# STM32U335 register map
File version: 1.0
CPU: CM33 r0p1, little endian, MPU, FPU, 4 interrupt priority bits
Registers are 32-bit, read-write, reset 0x0 unless marked. A register's access mark holds for its fields unless they carry their own. Offsets are from the block's base; [hi:lo] are bit positions.

## GTZC1_TZSC — GTZC1_TZSC Address block
Base 0x40032400
Same registers: GTZC1_TZSC_S 0x50032400
0x00 GTZC1_TZSC_CR — Secure privileged access only.
  [0] LCK — lock the configuration of GTZC1_TZSC_SECCFGRx and GTZC1_TZSC_PRIVCFGRx registers until next reset This bit is cleared by default and once set, it can not be reset until system reset.
    0=configuration of all GTZC1_TZSC_SECCFGRx and GTZC1_TZSC_PRIVCFGRx registers not locked; 1=configuration of all GTZC1_TZSC_SECCFGRx and GTZC1_TZSC_PRIVCFGRx registers locked
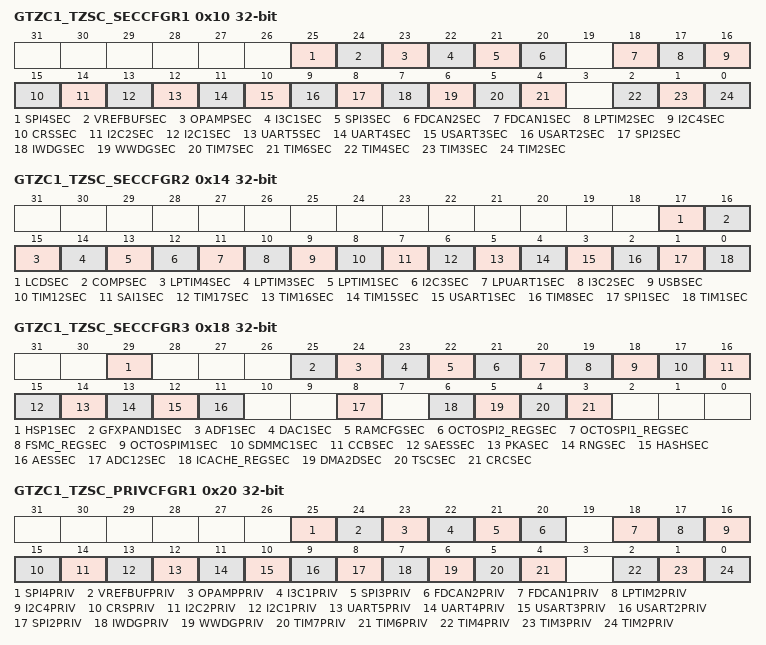
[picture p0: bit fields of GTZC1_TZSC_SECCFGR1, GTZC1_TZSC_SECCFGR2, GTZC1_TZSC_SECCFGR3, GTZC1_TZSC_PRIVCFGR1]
0x10 GTZC1_TZSC_SECCFGR1 — Write-secure access only. This register can be written only by secure privileged transaction when corresponding GTZC1_TZSC_PRIVCFGR register signal is set to 1. If a given PRIV bit is not set, the equivalent SEC bit can be written by secure unprivileged transaction. Read accesses are authorized for any type of transactions, secure or not, privileged or not.
  [all] fields
    0=non-secure; 1=secure
  [25] SPI4SEC — secure access mode for SPI4 Note: this bit is only available on STM32U3B5/3C5.
  [24] VREFBUFSEC — secure access mode for VREFBUF Note: this bit is not available on STM32U335/345.
  [23] OPAMPSEC — secure access mode for OPAMP
  [22] I3C1SEC — secure access mode for I3C1
  [21] SPI3SEC — secure access mode for SPI3 Note: this bit is not available on STM32U335/345.
  [20] FDCAN2SEC — secure access mode for FDCAN2 Caution: The FDCAN SRAM is secure only when all FDCAN instances are configures as secure Note: This bit is only available on STM32U3B5/3C5
  [18] FDCAN1SEC — secure access mode for FDCAN1 Caution: The FDCAN SRAM is secure only when all FDCAN instances are configures as secure Note: This bit is not available on STM32U356/366.
  [17] LPTIM2SEC — secure access mode for LPTIM2
  [16] I2C4SEC — secure access mode for I2C4 Note: This bit is only available on STM32U3B5/3C5
  [15] CRSSEC — secure access mode for CRS
  [14] I2C2SEC — secure access mode for I2C2 Note: This bit is only available on STM32U375/385, STM32U396/3A6, and STM32U3B5/3C5.
  [13] I2C1SEC — secure access mode for I2C1
  [12] UART5SEC — secure access mode for UART5 Note: This bit is not available on STM32U335/345.
  [11] UART4SEC — secure access mode for UART4
  [10] USART3SEC — secure access mode for USART3
  [9] USART2SEC — secure access mode for USART2 Note: This bit is only available on STM32U396/3A6 and STM32U3B5/3C5.
  [8] SPI2SEC — secure access mode for SPI2
  [7] IWDGSEC — secure access mode for IWDG
  [6] WWDGSEC — secure access mode for WWDG
  [5] TIM7SEC — secure access mode for TIM7 0: non-secure 1: secure
  [4] TIM6SEC — secure access mode for TIM6 0: non-secure 1: secure
  [2] TIM4SEC — secure access mode for TIM4 0: non-secure 1: secure
  [1] TIM3SEC — secure access mode for TIM3 0: non-secure 1: secure
  [0] TIM2SEC — secure access mode for TIM2 0: non-secure 1: secure
0x14 GTZC1_TZSC_SECCFGR2 — Write-secure access only. This register can be written only by secure privileged transaction when corresponding GTZC1_TZSC_PRIVCFGR register signal is set to 1. If a given PRIV is not set, the equivalent SEC bit can be written by secure unprivileged transaction. Read accesses are authorized for any type of transactions, secure or not, privileged or not.
  [all] fields
    0=non-secure; 1=secure
  [17] LCDSEC — secure access mode for LCD Note: This bit is only available on STM32U356/366 and STM32U396/3A6.
  [16] COMPSEC — secure access mode for COMP
  [15] LPTIM4SEC — secure access mode for LPTIM4 0: non-secure 1: secure
  [14] LPTIM3SEC — secure access mode for LPTIM3 0: non-secure 1: secure
  [13] LPTIM1SEC — secure access mode for LPTIM1 0: non-secure 1: secure
  [12] I2C3SEC — secure access mode for I2C3
  [11] LPUART1SEC — secure access mode for LPUART1
  [10] I3C2SEC — secure access mode for I3C2 Note: This bit is only available on STM32U375/385, STM32U396/3A6, and STM32U3B5/3C5.
  [9] USBSEC — secure access mode for USB
  [8] TIM12SEC — secure access mode for TIM12SEC Note: This bit is only available on STM32U396/3A6 and STM32U3B5/3C5.
  [7] SAI1SEC — secure access mode for SAI1 Note: This bit is only available on STM32U375/385, STM32U396/3A6, and STM32U3B5/3C5.
  [6] TIM17SEC — secure access mode for TIM17 0: non-secure 1: secure
  [5] TIM16SEC — secure access mode for TIM16 0: non-secure 1: secure
  [4] TIM15SEC — secure access mode for TIM15 0: non-secure 1: secure
  [3] USART1SEC — secure access mode for USART1
  [2] TIM8SEC — secure access mode for TIM8 Note: This bit is only available on STM32U396/3A6, and STM32U3B5/3C5.
  [1] SPI1SEC — secure access mode for SPI1
  [0] TIM1SEC — secure access mode for TIM1 0: non-secure 1: secure
0x18 GTZC1_TZSC_SECCFGR3 — Write-secure access only. This register can be written only by secure privileged transaction when corresponding GTZC1_TZSC_PRIVCFGR register signal is set to 1. If a given PRIV is not set, the equivalent SEC bit can be written by secure unprivileged transaction. Read accesses are authorized for any type of transactions, secure or not, privileged or not.
  [all] fields
    0=non-secure; 1=secure
  [29] HSP1SEC — secure access mode for HSP1 Note: This bit is only available on STM32U396/3A6 and STM32U3B5/3C5.
  [25] GFXPAND1SEC — secure access mode for GFXPAND1 Note: This bit is only available on STM32U396/3A6.
  [24] ADF1SEC — secure access mode for ADF1 Note: This bit is not available on STM32U356/366.
  [23] DAC1SEC — secure access mode for DAC1
  [22] RAMCFGSEC — secure access mode for RAMCFG
  [21] OCTOSPI2_REGSEC — secure access mode for OCTOSPI2 registers Note: This bit is only available on STM32U396/3A6.
  [20] OCTOSPI1_REGSEC — secure access mode for OCTOSPI1 registers
  [19] FSMC_REGSEC — secure access mode for FSMC registers Note: This bit is only available on STM32U396/3A6.
  [18] OCTOSPIM1SEC — secure access mode for OCTOSPIM Note: This bit is only available on STM32U396/3A6.
  [17] SDMMC1SEC — secure access mode for SDMMC1 Note: This bit is only available on STM32U375/385, STM32U396/3A6, and STM32U3B5/3C5.
  [16] CCBSEC — secure access mode for CCB Note: This bit is not available on STM32U335/345.
  [15] SAESSEC — secure access mode for SAES Note: This bit is not available on STM32U335/345.
  [14] PKASEC — secure access mode for PKA Note: This bit is not available on STM32U335/345.
  [13] RNGSEC — secure access mode for RNG
  [12] HASHSEC — secure access mode for HASH
  [11] AESSEC — secure access mode for AES
  [8] ADC12SEC — secure access mode for ADC1 and ADC2
  [6] ICACHE_REGSEC — secure access mode for ICACHE registers
  [5] DMA2DSEC — secure access mode for DMA2D Note: This bit is only available on STM32U396/3A6.
  [4] TSCSEC — secure access mode for TSC
  [3] CRCSEC — secure access mode for CRC
0x20 GTZC1_TZSC_PRIVCFGR1 — Write-privileged access only. This register can be read or written only by secure privileged transaction when corresponding GTZC1_TZSC_SECCFGR register signal is set to1. If a given SEC bit is not set, the equivalent PRIV bit can be read/written by non-secure privileged transaction. Read accesses are authorized for any type of transactions, secure or not, privileged or not.
  [25] SPI4PRIV — privileged access mode for SPI4 Note: this bit is only available on STM32U3B5/3C5.
    0=non-secure; 1=secure
  [24] VREFBUFPRIV — privileged access mode for VREFBUF Note: this bit is not available on STM32U335/345.
    0=unprivileged; 1=privileged
  [23] OPAMPPRIV — privileged access mode for OPAMP
    0=unprivileged; 1=privileged
  [22] I3C1PRIV — privileged access mode for I3C1
    0=unprivileged; 1=privileged
  [21] SPI3PRIV — privileged access mode for SPI3 Note: this bit is not available on STM32U335/345.
    0=unprivileged; 1=privileged
  [20] FDCAN2PRIV — privileged access mode for FDCAN2 Caution: The FDCAN SRAM is privileged only when all FDCAN instances are configured as privileged Note: This bit is only available on STM32U3B5/3C5.
    0=non-secure; 1=secure
  [18] FDCAN1PRIV — privileged access mode for FDCAN1 Caution: The FDCAN SRAM is privileged only when all FDCAN instances are configured as privileged Note: This bit is not available on STM32U356/366.
    0=non-secure; 1=secure
  [17] LPTIM2PRIV — privileged access mode for LPTIM2
    0=unprivileged; 1=privileged
  [16] I2C4PRIV — privileged access mode for I2C4 Note: This bit is only available on STM32U3B5/3C5.
    0=non-secure; 1=secure
  [15] CRSPRIV — privileged access mode for CRS
    0=unprivileged; 1=privileged
  [14] I2C2PRIV — privileged access mode for I2C2 Note: This bit is only available on STM32U375/385, STM32U396/3A6, and STM32U3B5/3C5.
    0=non-secure; 1=secure
  [13] I2C1PRIV — privileged access mode for I2C1
    0=unprivileged; 1=privileged
  [12] UART5PRIV — privileged access mode for UART5 Note: This bit is not available on STM32U335/345.
    0=unprivileged; 1=privileged
  [11] UART4PRIV — privileged access mode for UART4
    0=unprivileged; 1=privileged
  [10] USART3PRIV — privileged access mode for USART3
    0=unprivileged; 1=privileged
  [9] USART2PRIV — privileged access mode for USART2 Note: This bit is only available on STM32U396/3A6 and STM32U3B5/3C5.
    0=non-secure; 1=secure
  [8] SPI2PRIV — privileged access mode for SPI2
    0=unprivileged; 1=privileged
  [7] IWDGPRIV — privileged access mode for IWDG
    0=unprivileged; 1=privileged
  [6] WWDGPRIV — privileged access mode for WWDG
    0=unprivileged; 1=privileged
  [5] TIM7PRIV — privileged access mode for TIM7 0: unprivileged 1: privileged
    0=unprivileged; 1=privileged
  [4] TIM6PRIV — privileged access mode for TIM6 0: unprivileged 1: privileged
    0=unprivileged; 1=privileged
  [2] TIM4PRIV — privileged access mode for TIM4 0: unprivileged 1: privileged
    0=unprivileged; 1=privileged
  [1] TIM3PRIV — privileged access mode for TIM3 0: unprivileged 1: privileged
    0=unprivileged; 1=privileged
  [0] TIM2PRIV — privileged access mode for TIM2 0: unprivileged 1: privileged
    0=unprivileged; 1=privileged
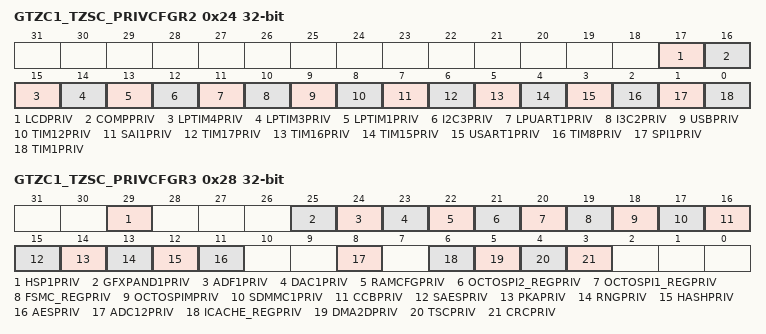
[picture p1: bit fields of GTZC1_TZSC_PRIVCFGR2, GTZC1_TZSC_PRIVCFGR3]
0x24 GTZC1_TZSC_PRIVCFGR2 — Write-privileged access only. This register can be read or written only by secure privileged transaction when corresponding GTZC1_TZSC_SECCFGR register signal is set to1. If a given SEC bit is not set, the equivalent PRIV bit can be read/written by non-secure privileged transaction. Read accesses are authorized for any type of transactions, secure or not, privileged or not.
  [17] LCDPRIV — privileged access mode for LCD Note: This bit is only available on STM32U356/366 and STM32U396/3A6.
    0=non-secure; 1=secure
  [16] COMPPRIV — privileged access mode for COMP
    0=unprivileged; 1=privileged
  [15] LPTIM4PRIV — privileged access mode for LPTIM4 0: unprivileged 1: privileged
    0=unprivileged; 1=privileged
  [14] LPTIM3PRIV — privileged access mode for LPTIM3 0: unprivileged 1: privileged
    0=unprivileged; 1=privileged
  [13] LPTIM1PRIV — privileged access mode for LPTIM1 0: unprivileged 1: privileged
    0=unprivileged; 1=privileged
  [12] I2C3PRIV — privileged access mode for I2C3
    0=unprivileged; 1=privileged
  [11] LPUART1PRIV — privileged access mode for LPUART1
    0=unprivileged; 1=privileged
  [10] I3C2PRIV — privileged access mode for I3C2 Note: This bit is only available on STM32U375/385, STM32U396/3A6, and STM32U3B5/3C5.
    0=unprivileged; 1=privileged
  [9] USBPRIV — privileged access mode for USB
    0=unprivileged; 1=privileged
  [8] TIM12PRIV — privileged access mode for TIM12 Note: This bit is only available on STM32U396/3A6 and STM32U3B5/3C5.
    0=unprivileged; 1=privileged
  [7] SAI1PRIV — privileged access mode for SAI1 Note: This bit is only available on STM32U375/385, STM32U396/3A6, and STM32U3B5/3C5.
    0=unprivileged; 1=privileged
  [6] TIM17PRIV — privileged access mode for TIM17 0: unprivileged 1: privileged
    0=unprivileged; 1=privileged
  [5] TIM16PRIV — privileged access mode for TIM16 0: unprivileged 1: privileged
    0=unprivileged; 1=privileged
  [4] TIM15PRIV — privileged access mode for TIM15 0: unprivileged 1: privileged
    0=unprivileged; 1=privileged
  [3] USART1PRIV — privileged access mode for USART1
    0=unprivileged; 1=privileged
  [2] TIM8PRIV — privileged access mode for TIM8 Note: This bit is only available on STM32U396/3A6, and STM32U3B5/3C5.
    0=unprivileged; 1=privileged
  [1] SPI1PRIV — privileged access mode for SPI1
    0=unprivileged; 1=privileged
  [0] TIM1PRIV — privileged access mode for TIM1 0: unprivileged 1: privileged
    0=unprivileged; 1=privileged
0x28 GTZC1_TZSC_PRIVCFGR3 — Write-privileged access only. This register can be read or written only by secure privileged transaction when corresponding GTZC1_TZSC_SECCFGR register signal is set to1. If a given SEC bit is not set, the equivalent PRIV bit can be read/written by non-secure privileged transaction. Read accesses are authorized for any type of transactions, secure or not, privileged or not.
  [all] fields
    0=unprivileged; 1=privileged
  [29] HSP1PRIV — privileged access mode for HSP1 Note: This bit is only available on STM32U396/3A6 and STM32U3B5/3C5.
  [25] GFXPAND1PRIV — privileged access mode for GFXPAND1 Note: This bit is only available on STM32U396/3A6.
  [24] ADF1PRIV — privileged access mode for ADF1 Note: This bit is not available on STM32U356/366.
  [23] DAC1PRIV — privileged access mode for DAC1
  [22] RAMCFGPRIV — privileged access mode for RAMCFG
  [21] OCTOSPI2_REGPRIV — privileged access mode for OCTOSPI2 registers Note: This bit is only available on STM32U396/3A6.
  [20] OCTOSPI1_REGPRIV — privileged access mode for OCTOSPI1 registers
  [19] FSMC_REGPRIV — privileged access mode for FSMC registers Note: This bit is only available on STM32U396/3A6.
  [18] OCTOSPIMPRIV — priviliged access mode for OCTOSPIM Note: This bit is only available on STM32U396/3A6.
  [17] SDMMC1PRIV — privileged access mode for SDMMC1 Note: This bit is only available on STM32U375/385, STM32U396/3A6, and STM32U3B5/3C5.
  [16] CCBPRIV — privileged access mode for CCB Note: This bit is not available on STM32U335/345.
  [15] SAESPRIV — privileged access mode for SAES Note: This bit is not available on STM32U335/345.
  [14] PKAPRIV — privileged access mode for PKA Note: This bit is not available on STM32U335/345.
  [13] RNGPRIV — privileged access mode for RNG
  [12] HASHPRIV — privileged access mode for HASH
  [11] AESPRIV — privileged access mode for AES
  [8] ADC12PRIV — privileged access mode for ADC1 and ADC2
  [6] ICACHE_REGPRIV — privileged access mode for ICACHE registers
  [5] DMA2DPRIV — privileged access mode for DMA2D Note: This bit is only available on STM32U396/3A6.
  [4] TSCPRIV — privileged access mode for TSC
  [3] CRCPRIV — privileged access mode for CRC
